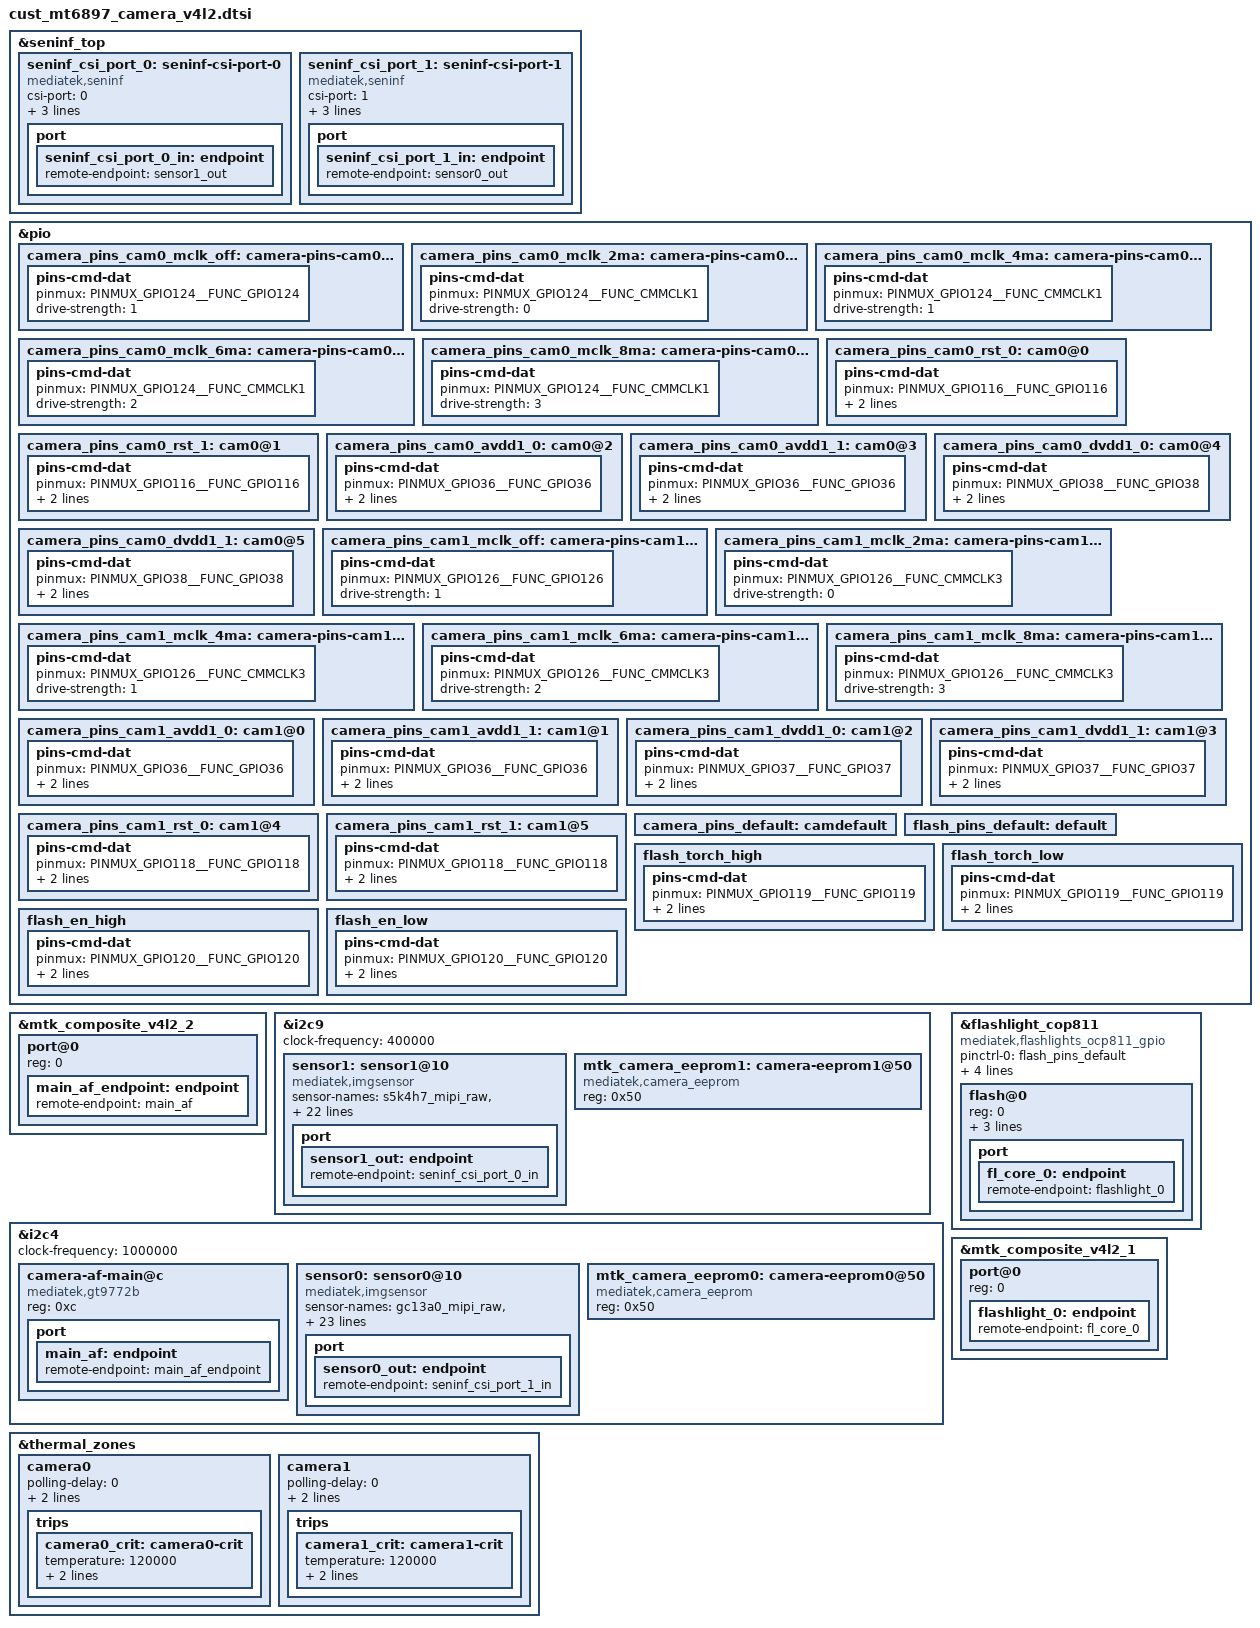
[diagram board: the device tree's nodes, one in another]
// SPDX-License-Identifier: GPL-2.0
/* Copyright (c) 2020 MediaTek Inc. */
#include <dt-bindings/clock/mt6897-clk.h>


&seninf_top {
		seninf_csi_port_0: seninf-csi-port-0 {
			compatible = "mediatek,seninf";
			csi-port = "0";
			dphy-settle-delay-dt = <17>;
			nvmem-cells = <&csi_efuse0>;
			nvmem-cell-names = "rg_csi";
			port {
				seninf_csi_port_0_in: endpoint {
					remote-endpoint = <&sensor1_out>;
				};
			};
		};

		seninf_csi_port_1: seninf-csi-port-1 {
			compatible = "mediatek,seninf";
			csi-port = "1";
			hs-trail-parameter = <0x20>;
			nvmem-cells = <&csi_efuse1>;
			nvmem-cell-names = "rg_csi";
			port {
				seninf_csi_port_1_in: endpoint {
					remote-endpoint = <&sensor0_out>;
				};
			};
		};

};

/* CAMERA GPIO standardization */
&pio {
	/*rear clk*/
	camera_pins_cam0_mclk_off: camera-pins-cam0-mclk-off {
		pins-cmd-dat {
			pinmux = <PINMUX_GPIO124__FUNC_GPIO124>;
			drive-strength = <1>;
		};
	};
	camera_pins_cam0_mclk_2ma: camera-pins-cam0-mclk-2ma {
		pins-cmd-dat {
			pinmux = <PINMUX_GPIO124__FUNC_CMMCLK1>;
			drive-strength = <0>;
		};
	};
	camera_pins_cam0_mclk_4ma: camera-pins-cam0-mclk-4ma {
		pins-cmd-dat {
			pinmux = <PINMUX_GPIO124__FUNC_CMMCLK1>;
			drive-strength = <1>;
		};
	};
	camera_pins_cam0_mclk_6ma: camera-pins-cam0-mclk-6ma {
		pins-cmd-dat {
			pinmux = <PINMUX_GPIO124__FUNC_CMMCLK1>;
			drive-strength = <2>;
		};
	};
	camera_pins_cam0_mclk_8ma: camera-pins-cam0-mclk-8ma {
		pins-cmd-dat {
			pinmux = <PINMUX_GPIO124__FUNC_CMMCLK1>;
			drive-strength = <3>;
		};
	};
	/*reat rest*/
	camera_pins_cam0_rst_0: cam0@0 {
		pins-cmd-dat {
			pinmux = <PINMUX_GPIO116__FUNC_GPIO116>;
			slew-rate = <1>;
			output-low;
		};
	};
	camera_pins_cam0_rst_1: cam0@1 {
		pins-cmd-dat {
			pinmux = <PINMUX_GPIO116__FUNC_GPIO116>;
			slew-rate = <1>;
			output-high;
		};
	};
	/*rear avdd*/
	camera_pins_cam0_avdd1_0: cam0@2 {
		pins-cmd-dat {
			pinmux = <PINMUX_GPIO36__FUNC_GPIO36>;
			slew-rate = <1>;
			output-low;
		};
	};
	camera_pins_cam0_avdd1_1: cam0@3 {
		pins-cmd-dat {
			pinmux = <PINMUX_GPIO36__FUNC_GPIO36>;
			slew-rate = <1>;
			output-high;
		};
	};

	/*rear dvdd*/
	camera_pins_cam0_dvdd1_0: cam0@4 {
		pins-cmd-dat {
			pinmux = <PINMUX_GPIO38__FUNC_GPIO38>;
			slew-rate = <1>;
			output-low;
		};
	};
	camera_pins_cam0_dvdd1_1: cam0@5 {
		pins-cmd-dat {
			pinmux = <PINMUX_GPIO38__FUNC_GPIO38>;
			slew-rate = <1>;
			output-high;
		};
	};


	/*front*/
	camera_pins_cam1_mclk_off: camera-pins-cam1-mclk-off {
		pins-cmd-dat {
			pinmux = <PINMUX_GPIO126__FUNC_GPIO126>;
			drive-strength = <1>;
		};
	};
	camera_pins_cam1_mclk_2ma: camera-pins-cam1-mclk-2ma {
		pins-cmd-dat {
			pinmux = <PINMUX_GPIO126__FUNC_CMMCLK3>;
			drive-strength = <0>;
		};
	};
	camera_pins_cam1_mclk_4ma: camera-pins-cam1-mclk-4ma {
		pins-cmd-dat {
			pinmux = <PINMUX_GPIO126__FUNC_CMMCLK3>;
			drive-strength = <1>;
		};
	};
	camera_pins_cam1_mclk_6ma: camera-pins-cam1-mclk-6ma {
		pins-cmd-dat {
			pinmux = <PINMUX_GPIO126__FUNC_CMMCLK3>;
			drive-strength = <2>;
		};
	};
	camera_pins_cam1_mclk_8ma: camera-pins-cam1-mclk-8ma {
		pins-cmd-dat {
			pinmux = <PINMUX_GPIO126__FUNC_CMMCLK3>;
			drive-strength = <3>;
		};
	};

	/*front avdd*/
	camera_pins_cam1_avdd1_0: cam1@0 {
		pins-cmd-dat {
			pinmux = <PINMUX_GPIO36__FUNC_GPIO36>;
			slew-rate = <1>;
			output-low;
		};
	};

	camera_pins_cam1_avdd1_1: cam1@1 {
		pins-cmd-dat {
			pinmux = <PINMUX_GPIO36__FUNC_GPIO36>;
			slew-rate = <1>;
			output-high;
		};
	};
	/*front dvdd*/
	camera_pins_cam1_dvdd1_0: cam1@2 {
		pins-cmd-dat {
			pinmux = <PINMUX_GPIO37__FUNC_GPIO37>;
			slew-rate = <1>;
			output-low;
		};
	};

	camera_pins_cam1_dvdd1_1: cam1@3 {
		pins-cmd-dat {
			pinmux = <PINMUX_GPIO37__FUNC_GPIO37>;
			slew-rate = <1>;
			output-high;
		};
	};

        /*front rest*/
	camera_pins_cam1_rst_0: cam1@4 {
		pins-cmd-dat {
			pinmux = <PINMUX_GPIO118__FUNC_GPIO118>;
			slew-rate = <1>;
			output-low;
		};
	};
	camera_pins_cam1_rst_1: cam1@5 {
		pins-cmd-dat {
			pinmux = <PINMUX_GPIO118__FUNC_GPIO118>;
			slew-rate = <1>;
			output-high;
		};
	};
	camera_pins_default: camdefault {
	};
};
/* CAMERA GPIO end */

&mtk_composite_v4l2_2 {
	#address-cells = <1>;
	#size-cells = <0>;

	port@0 {
		reg = <0>;
		main_af_endpoint: endpoint {
			remote-endpoint = <&main_af>;
		};
	};
};

&i2c9 {
	status = "okay";
	clock-frequency = <400000>;
	#address-cells = <1>;
	#size-cells = <0>;

	sensor1: sensor1@10 {
		compatible = "mediatek,imgsensor";
		sensor-names = "s5k4h7_mipi_raw",
		               "sc820cs_mipi_raw";
		reg = <0x10>;
		#thermal-sensor-cells = <0>;

		pinctrl-names = "mclk_off",
				"mclk_2mA",
				"mclk_4mA",
				"mclk_6mA",
				"mclk_8mA",
				"avdd1_off",
				"avdd1_on",
				"dvdd1_off",
				"dvdd1_on",
				"rst_low",
				"rst_high";
		pinctrl-0 = <&camera_pins_cam1_mclk_off>;
		pinctrl-1 = <&camera_pins_cam1_mclk_2ma>;
		pinctrl-2 = <&camera_pins_cam1_mclk_4ma>;
		pinctrl-3 = <&camera_pins_cam1_mclk_6ma>;
		pinctrl-4 = <&camera_pins_cam1_mclk_8ma>;
		pinctrl-5 = <&camera_pins_cam1_avdd1_0>;
		pinctrl-6 = <&camera_pins_cam1_avdd1_1>;
		pinctrl-7 = <&camera_pins_cam1_dvdd1_0>;
		pinctrl-8 = <&camera_pins_cam1_dvdd1_1>;
		pinctrl-9 = <&camera_pins_cam1_rst_0>;
		pinctrl-10 = <&camera_pins_cam1_rst_1>;

		//avdd-supply = <&rt5133_ldo6>;
		//dvdd-supply = <&rt5133_ldo7>;
		dovdd-supply = <&mt6368_vsim2>;
		//afvdd-supply = <&rt5133_ldo2>;

		clocks = <&topckgen_clk CLK_TOP_UNIVPLL_192M_D32>,
			<&topckgen_clk CLK_TOP_UNIVPLL_192M_D16>,
			<&topckgen_clk CLK_TOP_F26M_CK_D2>,
			<&topckgen_clk CLK_TOP_UNIVPLL_192M_D10>,
			<&topckgen_clk CLK_TOP_UNIVPLL_192M_D8>,
			<&topckgen_clk CLK_TOP_UNIVPLL_D6_D16>,
			<&topckgen_clk CLK_TOP_UNIVPLL_D6_D8>,
			<&topckgen_clk CLK_TOP_CAMTG4_SEL>;
		clock-names = "6", "12", "13", "19.2", "24", "26", "52", "mclk";

		status = "okay";

		port {
			sensor1_out: endpoint {
				remote-endpoint = <&seninf_csi_port_0_in>;
			};
		};
	};

	mtk_camera_eeprom1:camera-eeprom1@50 {
		compatible = "mediatek,camera_eeprom";
		reg = <0x50>;
		status = "okay";
	};
};

&i2c4 {
	status = "okay";
	clock-frequency = <1000000>;
	#address-cells = <1>;
	#size-cells = <0>;

	camera-af-main@c {
		compatible = "mediatek,gt9772b";
		reg = <0xc>;
		//vdd-supply = <&mt6368_vibr>;
		port {
			main_af: endpoint {
				remote-endpoint = <&main_af_endpoint>;
			};
		};
	};

	sensor0: sensor0@10 {
		compatible = "mediatek,imgsensor";
		sensor-names = "gc13a0_mipi_raw",
                              "ov13b10_mipi_raw";
		reg = <0x10>;
		#thermal-sensor-cells = <0>;
		pinctrl-names = "mclk_off",
				"mclk_2mA",
				"mclk_4mA",
				"mclk_6mA",
				"mclk_8mA",
				"avdd1_off",
				"avdd1_on",
				"dvdd1_off",
				"dvdd1_on",
				"rst_low",
				"rst_high";
		pinctrl-0 = <&camera_pins_cam0_mclk_off>;
		pinctrl-1 = <&camera_pins_cam0_mclk_2ma>;
		pinctrl-2 = <&camera_pins_cam0_mclk_4ma>;
		pinctrl-3 = <&camera_pins_cam0_mclk_6ma>;
		pinctrl-4 = <&camera_pins_cam0_mclk_8ma>;
		pinctrl-5 = <&camera_pins_cam0_avdd1_0>;
		pinctrl-6 = <&camera_pins_cam0_avdd1_1>;
		pinctrl-7 = <&camera_pins_cam0_dvdd1_0>;
		pinctrl-8 = <&camera_pins_cam0_dvdd1_1>;
		pinctrl-9 = <&camera_pins_cam0_rst_0>;
		pinctrl-10 = <&camera_pins_cam0_rst_1>;

		//avdd-supply = <&rt5133_ldo6>;
		//dvdd-supply = <&rt5133_gpio3>;
		dovdd-supply = <&mt6368_vsim2>;
		afvdd-supply = <&mt6368_vibr>;

		clocks = <&topckgen_clk CLK_TOP_UNIVPLL_192M_D32>,
			<&topckgen_clk CLK_TOP_UNIVPLL_192M_D16>,
			<&topckgen_clk CLK_TOP_F26M_CK_D2>,
			<&topckgen_clk CLK_TOP_UNIVPLL_192M_D10>,
			<&topckgen_clk CLK_TOP_UNIVPLL_192M_D8>,
			<&topckgen_clk CLK_TOP_UNIVPLL_D6_D16>,
			<&topckgen_clk CLK_TOP_UNIVPLL_D6_D8>,
			<&topckgen_clk CLK_TOP_CAMTG2_SEL>;
		clock-names = "6", "12", "13", "19.2", "24", "26", "52", "mclk";

		status = "okay";

		port {
			sensor0_out: endpoint {
				remote-endpoint = <&seninf_csi_port_1_in>;
			};
		};
	};

	mtk_camera_eeprom0:camera-eeprom0@50 {
		compatible = "mediatek,camera_eeprom";
		reg = <0x50>;
		status = "okay";
	};
};


&pio {
	flash_pins_default: default{
	};

	flash_torch_high: flash_torch_high {
		pins-cmd-dat {
			pinmux = <PINMUX_GPIO119__FUNC_GPIO119>;
			slew-rate = <1>;
			output-high;
		};
	};

	flash_torch_low: flash_torch_low {
		pins-cmd-dat {
			pinmux = <PINMUX_GPIO119__FUNC_GPIO119>;
			slew-rate = <1>;
			output-low;
		};
	};

	flash_en_high: flash_en_high {
		pins-cmd-dat {
			pinmux = <PINMUX_GPIO120__FUNC_GPIO120>;
			slew-rate = <1>;
			output-high;
		};
	};

	flash_en_low: flash_en_low {
		pins-cmd-dat {
			pinmux = <PINMUX_GPIO120__FUNC_GPIO120>;
			slew-rate = <1>;
			output-low;
		};
	};
};

&flashlight_cop811{
	compatible = "mediatek,flashlights_ocp811_gpio";

	pinctrl-names = "default",
				"flash_torch_high",
				"flash_torch_low",
				"flash_en_high",
				"flash_en_low";

	pinctrl-0 = <&flash_pins_default>;
	pinctrl-1 = <&flash_torch_high>;
	pinctrl-2 = <&flash_torch_low>;
	pinctrl-3 = <&flash_en_high>;
	pinctrl-4 = <&flash_en_low>;

	flash@0{
		reg = <0>;
		type = <0>;
		ct = <0>;
		part = <0>;
		port {
			fl_core_0: endpoint {
				remote-endpoint = <&flashlight_0>;
			};
		};
	};

};

&mtk_composite_v4l2_1 {
	#address-cells = <1>;
	#size-cells = <0>;

	port@0 {
		reg = <0>;
		flashlight_0: endpoint {
			remote-endpoint = <&fl_core_0>;
		};
	};
};


&thermal_zones {
	camera0: camera0 {
		polling-delay = <0>; /* milliseconds */
		polling-delay-passive = <0>; /* milliseconds */
		thermal-sensors = <&sensor0>;
		trips {
			camera0_crit: camera0-crit {
				temperature = <120000>;
				hysteresis = <2000>;
				type = "passive";
			};
		};
	};
	camera1: camera1 {
		polling-delay = <0>; /* milliseconds */
		polling-delay-passive = <0>; /* milliseconds */
		thermal-sensors = <&sensor1>;
		trips {
			camera1_crit: camera1-crit {
				temperature = <120000>;
				hysteresis = <2000>;
				type = "passive";
			};
		};
	};
};


